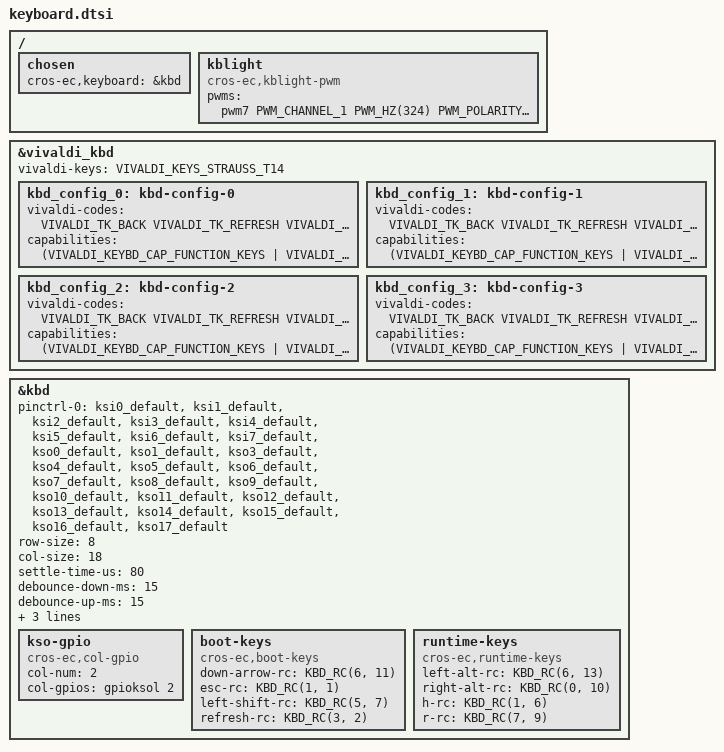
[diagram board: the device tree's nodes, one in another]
/* Copyright 2024 The ChromiumOS Authors
 * Use of this source code is governed by a BSD-style license that can be
 * found in the LICENSE file.
 */

 / {
	chosen {
		cros-ec,keyboard = &kbd;
	};

	kblight: kblight {
		compatible = "cros-ec,kblight-pwm";
		pwms = <&pwm7 PWM_CHANNEL_1 PWM_HZ(324) PWM_POLARITY_NORMAL>;
	};
};


&vivaldi_kbd {
	vivaldi-keys = <VIVALDI_KEYS_STRAUSS_T14>;

	/* without kblight & numpad */
	kbd_config_0: kbd-config-0{
		vivaldi-codes = <
			VIVALDI_TK_BACK			/* T1 */
			VIVALDI_TK_REFRESH		/* T2 */
			VIVALDI_TK_FULLSCREEN		/* T3 */
			VIVALDI_TK_OVERVIEW		/* T4 */
			VIVALDI_TK_SNAPSHOT		/* T5 */
			VIVALDI_TK_BRIGHTNESS_DOWN	/* T6 */
			VIVALDI_TK_BRIGHTNESS_UP	/* T7 */
			VIVALDI_TK_DICTATE		/* T8 */
			VIVALDI_TK_ACCESSIBILITY	/* T9 */
			VIVALDI_TK_PLAY_PAUSE		/* T10 */
			VIVALDI_TK_MICMUTE		/* T11 */
			VIVALDI_TK_VOL_MUTE		/* T12 */
			VIVALDI_TK_VOL_DOWN		/* T13 */
			VIVALDI_TK_VOL_UP		/* T14 */
		>;
		capabilities = < (VIVALDI_KEYBD_CAP_FUNCTION_KEYS |
					VIVALDI_KEYBD_CAP_SCRNLOCK_KEY |
					VIVALDI_KEYBD_CAP_ASSISTANT_KEY) >;
	};

	/* without kblight & with numpad */
	kbd_config_1: kbd-config-1 {
		vivaldi-codes = <
			VIVALDI_TK_BACK			/* T1 */
			VIVALDI_TK_REFRESH		/* T2 */
			VIVALDI_TK_FULLSCREEN		/* T3 */
			VIVALDI_TK_OVERVIEW		/* T4 */
			VIVALDI_TK_SNAPSHOT		/* T5 */
			VIVALDI_TK_BRIGHTNESS_DOWN	/* T6 */
			VIVALDI_TK_BRIGHTNESS_UP	/* T7 */
			VIVALDI_TK_DICTATE		/* T8 */
			VIVALDI_TK_ACCESSIBILITY	/* T9 */
			VIVALDI_TK_PLAY_PAUSE		/* T10 */
			VIVALDI_TK_MICMUTE		/* T11 */
			VIVALDI_TK_VOL_MUTE		/* T12 */
			VIVALDI_TK_VOL_DOWN		/* T13 */
			VIVALDI_TK_VOL_UP		/* T14 */
		>;
		capabilities = < (VIVALDI_KEYBD_CAP_FUNCTION_KEYS |
					VIVALDI_KEYBD_CAP_SCRNLOCK_KEY |
					VIVALDI_KEYBD_CAP_NUMERIC_KEYPAD |
					VIVALDI_KEYBD_CAP_ASSISTANT_KEY) >;
	};

	/* with kblight & without numpad */
	kbd_config_2: kbd-config-2 {
		vivaldi-codes = <
			VIVALDI_TK_BACK			/* T1 */
			VIVALDI_TK_REFRESH		/* T2 */
			VIVALDI_TK_FULLSCREEN		/* T3 */
			VIVALDI_TK_OVERVIEW		/* T4 */
			VIVALDI_TK_SNAPSHOT		/* T5 */
			VIVALDI_TK_BRIGHTNESS_DOWN	/* T6 */
			VIVALDI_TK_BRIGHTNESS_UP	/* T7 */
			VIVALDI_TK_KBD_BKLIGHT_TOGGLE	/* T8 */
			VIVALDI_TK_DICTATE		/* T9 */
			VIVALDI_TK_ACCESSIBILITY	/* T10 */
			VIVALDI_TK_MICMUTE		/* T11 */
			VIVALDI_TK_VOL_MUTE		/* T12 */
			VIVALDI_TK_VOL_DOWN		/* T13 */
			VIVALDI_TK_VOL_UP		/* T14 */
		>;
		capabilities = < (VIVALDI_KEYBD_CAP_FUNCTION_KEYS |
					VIVALDI_KEYBD_CAP_SCRNLOCK_KEY |
					VIVALDI_KEYBD_CAP_ASSISTANT_KEY) >;
	};


	/* with kblight & with numpad */
	kbd_config_3: kbd-config-3 {
		vivaldi-codes = <
			VIVALDI_TK_BACK			/* T1 */
			VIVALDI_TK_REFRESH		/* T2 */
			VIVALDI_TK_FULLSCREEN		/* T3 */
			VIVALDI_TK_OVERVIEW		/* T4 */
			VIVALDI_TK_SNAPSHOT		/* T5 */
			VIVALDI_TK_BRIGHTNESS_DOWN	/* T6 */
			VIVALDI_TK_BRIGHTNESS_UP	/* T7 */
			VIVALDI_TK_KBD_BKLIGHT_TOGGLE	/* T8 */
			VIVALDI_TK_DICTATE		/* T9 */
			VIVALDI_TK_ACCESSIBILITY	/* T10 */
			VIVALDI_TK_MICMUTE		/* T11 */
			VIVALDI_TK_VOL_MUTE		/* T12 */
			VIVALDI_TK_VOL_DOWN		/* T13 */
			VIVALDI_TK_VOL_UP		/* T14 */
		>;
		capabilities = < (VIVALDI_KEYBD_CAP_FUNCTION_KEYS |
					VIVALDI_KEYBD_CAP_SCRNLOCK_KEY |
					VIVALDI_KEYBD_CAP_NUMERIC_KEYPAD |
					VIVALDI_KEYBD_CAP_ASSISTANT_KEY) >;
	};
};

&kbd {
	status = "okay";
	/* No KSO2 (it's inverted and implemented by GPIO) */
	pinctrl-0 = <&ksi0_default
		     &ksi1_default
		     &ksi2_default
		     &ksi3_default
		     &ksi4_default
		     &ksi5_default
		     &ksi6_default
		     &ksi7_default
		     &kso0_default
		     &kso1_default
		     &kso3_default
		     &kso4_default
		     &kso5_default
		     &kso6_default
		     &kso7_default
		     &kso8_default
		     &kso9_default
		     &kso10_default
		     &kso11_default
		     &kso12_default
		     &kso13_default
		     &kso14_default
		     &kso15_default
		     &kso16_default
		     &kso17_default
	>;
	pinctrl-names = "default";
	row-size = <8>;
	col-size = <18>;
	settle-time-us = <80>;
	debounce-down-ms = <15>;
	debounce-up-ms = <15>;
	actual-key-mask = <0x08 0xff 0xff 0xff 0xff 0xff 0xff 0xa4
			   0xff 0xff 0x55 0xff 0xff 0x40 0x0a 0x40
			   0xff 0xff>;
	kso-ignore-mask = <04>;

	kso-gpio {
		compatible = "cros-ec,col-gpio";
		col-num = <2>;
		col-gpios = <&gpioksol 2 GPIO_ACTIVE_HIGH>;
	};

	boot-keys {
		compatible = "cros-ec,boot-keys";
		down-arrow-rc = <KBD_RC(6, 11)>;
		esc-rc = <KBD_RC(1, 1)>;
		left-shift-rc = <KBD_RC(5, 7)>;
		refresh-rc = <KBD_RC(3, 2)>;
	};

	runtime-keys {
		compatible = "cros-ec,runtime-keys";
		left-alt-rc = <KBD_RC(6, 13)>;
		right-alt-rc = <KBD_RC(0, 10)>;
		h-rc = <KBD_RC(1, 6)>;
		r-rc = <KBD_RC(7, 9)>;
	};
};
